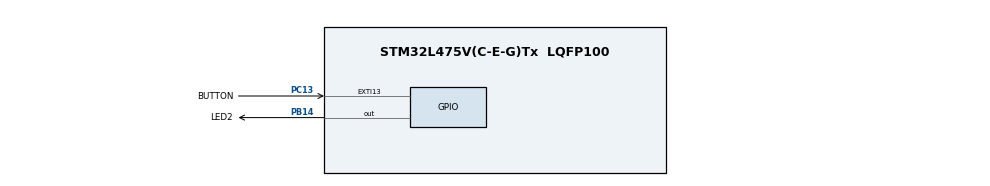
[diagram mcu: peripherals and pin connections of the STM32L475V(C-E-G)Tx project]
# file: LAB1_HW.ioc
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FREERTOS.Tasks01=defaultTask,24,128,StartDefaultTask,Default,NULL,Dynamic,NULL,NULL;myTask02,24,128,StartTask02,Default,NULL,Dynamic,NULL,NULL
Mcu.Family=STM32L4
Mcu.Name=STM32L475V(C-E-G)Tx
Mcu.Package=LQFP100
NVIC.EXTI15_10_IRQn=true\:5\:0\:false\:false\:true\:true\:true\:true\:true
NVIC.PriorityGroup=NVIC_PRIORITYGROUP_4
NVIC.TIM2_IRQn=true\:5\:0\:false\:false\:true\:true\:true\:true\:true
PA13\ (JTMS-SWDIO).Mode=Serial_Wire
PA13\ (JTMS-SWDIO).Signal=SYS_JTMS-SWDIO
PA14\ (JTCK-SWCLK).Mode=Serial_Wire
PA14\ (JTCK-SWCLK).Signal=SYS_JTCK-SWCLK
PB14.GPIO_Label=LED2
PB14.Signal=GPIO_Output
PC13.GPIO_Label=BUTTON
PC13.GPIO_ModeDefaultEXTI=GPIO_MODE_IT_RISING_FALLING
PC13.GPIO_PuPd=GPIO_NOPULL
PC13.Signal=GPXTI13
ProjectManager.HeapSize=0x200
ProjectManager.StackSize=0x400
ProjectManager.TargetToolchain=STM32CubeIDE
RCC.HSE_VALUE=8000000
RCC.HSI_VALUE=16000000
RCC.LSE_VALUE=32768
RCC.MSI_VALUE=4000000
RCC.VCOOutputFreq_Value=32000000
TIM2.AutoReloadPreload=TIM_AUTORELOAD_PRELOAD_ENABLE
TIM2.Period=9999
TIM2.Prescaler=3999
VP_FREERTOS_VS_CMSIS_V2.Mode=CMSIS_V2
VP_TIM2_VS_ClockSourceINT.Mode=Internal
board=custom

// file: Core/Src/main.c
/* USER CODE BEGIN Header */
/**
  ******************************************************************************
  * @file           : main.c
  * @brief          : Main program body
  ******************************************************************************
  * @attention
  *
  * Copyright (c) 2025 STMicroelectronics.
  * All rights reserved.
  *
  * This software is licensed under terms that can be found in the LICENSE file
  * in the root directory of this software component.
  * If no LICENSE file comes with this software, it is provided AS-IS.
  *
  ******************************************************************************
  */
/* USER CODE END Header */
#include "main.h"
#include "cmsis_os.h"

/* USER CODE BEGIN PTD */
#define basic  0
#define QA     1   // option problem_A: long-press detection + queue for Task_1

#define Question QA   // ← 換成 basic / QA 來切題目
// ---- 共用 ----
osSemaphoreId_t semTmr;     // Task_2 (10s) 用
osMutexId_t     mBlink;     // 互斥保護整段閃爍
extern TIM_HandleTypeDef htim2;
static volatile uint32_t g_lastBtnTick = 0; // 50 ms debounce（唯一一個）

// ---- basic 專用 ----
#if (Question == basic)
osSemaphoreId_t semBtn;     // Task_1 的按鍵通知
#endif

// ---- QA 專用（題目 A：長/短按用 queue）----
#if (Question == QA)
typedef enum { BTN_SHORT = 0, BTN_LONG = 1 } btn_evt_t;
osMessageQueueId_t qBtn;
osTimerId_t        tLong;         // 1s one-shot RTOS timer
static volatile uint8_t g_btnPressed = 0;
static volatile uint8_t g_longSent   = 0;
static volatile uint32_t g_pressMs = 0;   // 記錄按下當下的毫秒數
/*  提前宣告 callback 原型（讓編譯器知道它的存在） */
static void LongPressTimerCb(void *argument);
#endif
/* USER CODE END PTD */

TIM_HandleTypeDef htim2;

/* Definitions for defaultTask */
osThreadId_t defaultTaskHandle;
const osThreadAttr_t defaultTask_attributes = {
  .name = "defaultTask",
  .stack_size = 128 * 4,
  .priority = (osPriority_t) osPriorityNormal,
};
/* Definitions for myTask02 */
osThreadId_t myTask02Handle;
const osThreadAttr_t myTask02_attributes = {
  .name = "myTask02",
  .stack_size = 128 * 4,
  .priority = (osPriority_t) osPriorityNormal,
};

void SystemClock_Config(void);
static void MX_GPIO_Init(void);
static void MX_TIM2_Init(void);
void StartDefaultTask(void *argument);
void StartTask02(void *argument);

/* USER CODE BEGIN 0 */
#if (Question == QA)
static void LongPressTimerCb(void *argument)
{
    (void)argument;
    g_longSent = 1;
    uint8_t evt = BTN_LONG;
    /* 在 ISR/Timer context 下用 0 timeout 送訊息即可 */
    osMessageQueuePut(qBtn, &evt, 0, 0);
}
#endif
/* USER CODE END 0 */

int main(void)
{

  /* MCU Configuration--------------------------------------------------------*/

  /* Reset of all peripherals, Initializes the Flash interface and the Systick. */
  HAL_Init();

  /* Configure the system clock */
  SystemClock_Config();

  /* Initialize all configured peripherals */
  MX_GPIO_Init();
  MX_TIM2_Init();

  /* Init scheduler */
  osKernelInitialize();

  /* USER CODE BEGIN RTOS_MUTEX */
  mBlink = osMutexNew(NULL);
  /* add mutexes, ... */
  /* USER CODE END RTOS_MUTEX */

  /* USER CODE BEGIN RTOS_SEMAPHORES */
  semTmr = osSemaphoreNew(1, 0, NULL);
  // basic：用 semaphore 通知 Task_1
  #if (Question == basic)
  semBtn = osSemaphoreNew(1, 0, NULL);
  #endif

  // QA：用 queue + 1s timer 通知 Task_1
  #if (Question == QA)
  qBtn  = osMessageQueueNew(4, sizeof(uint8_t), NULL);
  tLong = osTimerNew(LongPressTimerCb, osTimerOnce, NULL, NULL);
  #endif
  /* add semaphores, ... */
  /* USER CODE END RTOS_SEMAPHORES */

  /* USER CODE BEGIN RTOS_TIMERS */
  HAL_TIM_Base_Start_IT(&htim2);
  /* start timers, add new ones, ... */
  /* USER CODE END RTOS_TIMERS */

  /* Create the thread(s) */
  /* creation of defaultTask */
  defaultTaskHandle = osThreadNew(StartDefaultTask, NULL, &defaultTask_attributes);

  /* creation of myTask02 */
  myTask02Handle = osThreadNew(StartTask02, NULL, &myTask02_attributes);

  /* Start scheduler */
  osKernelStart();

  /* We should never get here as control is now taken by the scheduler */

  /* Infinite loop */
  while (1)
  {

  }
}

void SystemClock_Config(void)
{
  RCC_OscInitTypeDef RCC_OscInitStruct = {0};
  RCC_ClkInitTypeDef RCC_ClkInitStruct = {0};

  /** Configure the main internal regulator output voltage
  */
  if (HAL_PWREx_ControlVoltageScaling(PWR_REGULATOR_VOLTAGE_SCALE1) != HAL_OK)
  {
    Error_Handler();
  }

  /** Initializes the RCC Oscillators according to the specified parameters
  * in the RCC_OscInitTypeDef structure.
  */
  RCC_OscInitStruct.OscillatorType = RCC_OSCILLATORTYPE_MSI;
  RCC_OscInitStruct.MSIState = RCC_MSI_ON;
  RCC_OscInitStruct.MSICalibrationValue = 0;
  RCC_OscInitStruct.MSIClockRange = RCC_MSIRANGE_6;
  RCC_OscInitStruct.PLL.PLLState = RCC_PLL_NONE;
  if (HAL_RCC_OscConfig(&RCC_OscInitStruct) != HAL_OK)
  {
    Error_Handler();
  }

  /** Initializes the CPU, AHB and APB buses clocks
  */
  RCC_ClkInitStruct.ClockType = RCC_CLOCKTYPE_HCLK|RCC_CLOCKTYPE_SYSCLK
                              |RCC_CLOCKTYPE_PCLK1|RCC_CLOCKTYPE_PCLK2;
  RCC_ClkInitStruct.SYSCLKSource = RCC_SYSCLKSOURCE_MSI;
  RCC_ClkInitStruct.AHBCLKDivider = RCC_SYSCLK_DIV1;
  RCC_ClkInitStruct.APB1CLKDivider = RCC_HCLK_DIV1;
  RCC_ClkInitStruct.APB2CLKDivider = RCC_HCLK_DIV1;

  if (HAL_RCC_ClockConfig(&RCC_ClkInitStruct, FLASH_LATENCY_0) != HAL_OK)
  {
    Error_Handler();
  }
}

static void MX_TIM2_Init(void)
{

  TIM_ClockConfigTypeDef sClockSourceConfig = {0};
  TIM_MasterConfigTypeDef sMasterConfig = {0};

  htim2.Instance = TIM2;
  htim2.Init.Prescaler = 3999;
  htim2.Init.CounterMode = TIM_COUNTERMODE_UP;
  htim2.Init.Period = 9999;
  htim2.Init.ClockDivision = TIM_CLOCKDIVISION_DIV1;
  htim2.Init.AutoReloadPreload = TIM_AUTORELOAD_PRELOAD_ENABLE;
  if (HAL_TIM_Base_Init(&htim2) != HAL_OK)
  {
    Error_Handler();
  }
  sClockSourceConfig.ClockSource = TIM_CLOCKSOURCE_INTERNAL;
  if (HAL_TIM_ConfigClockSource(&htim2, &sClockSourceConfig) != HAL_OK)
  {
    Error_Handler();
  }
  sMasterConfig.MasterOutputTrigger = TIM_TRGO_RESET;
  sMasterConfig.MasterSlaveMode = TIM_MASTERSLAVEMODE_DISABLE;
  if (HAL_TIMEx_MasterConfigSynchronization(&htim2, &sMasterConfig) != HAL_OK)
  {
    Error_Handler();
  }

}

static void MX_GPIO_Init(void)
{
  GPIO_InitTypeDef GPIO_InitStruct = {0};

  /* GPIO Ports Clock Enable */
  __HAL_RCC_GPIOC_CLK_ENABLE();
  __HAL_RCC_GPIOB_CLK_ENABLE();
  __HAL_RCC_GPIOA_CLK_ENABLE();

  /*Configure GPIO pin Output Level */
  HAL_GPIO_WritePin(LED2_GPIO_Port, LED2_Pin, GPIO_PIN_RESET);

  /*Configure GPIO pin : BUTTON_Pin */
  GPIO_InitStruct.Pin = BUTTON_Pin;
  GPIO_InitStruct.Mode = GPIO_MODE_IT_RISING_FALLING;
  GPIO_InitStruct.Pull = GPIO_NOPULL;
  HAL_GPIO_Init(BUTTON_GPIO_Port, &GPIO_InitStruct);

  /*Configure GPIO pin : LED2_Pin */
  GPIO_InitStruct.Pin = LED2_Pin;
  GPIO_InitStruct.Mode = GPIO_MODE_OUTPUT_PP;
  GPIO_InitStruct.Pull = GPIO_NOPULL;
  GPIO_InitStruct.Speed = GPIO_SPEED_FREQ_LOW;
  HAL_GPIO_Init(LED2_GPIO_Port, &GPIO_InitStruct);

  /* EXTI interrupt init*/
  HAL_NVIC_SetPriority(EXTI15_10_IRQn, 5, 0);
  HAL_NVIC_EnableIRQ(EXTI15_10_IRQn);

}

/* USER CODE BEGIN 4 */
void HAL_GPIO_EXTI_Callback(uint16_t GPIO_Pin)
{
	if (GPIO_Pin != BUTTON_Pin) return; //先確認就是 USER 按鍵
	// 共用：50 ms 去彈保持
	uint32_t now = HAL_GetTick();
	if (now - g_lastBtnTick < 50) return;
	g_lastBtnTick = now;

	#if (Question == basic)
	// basic：只在「按下」那個邊緣才喚醒
	if (HAL_GPIO_ReadPin(BUTTON_GPIO_Port, BUTTON_Pin) == GPIO_PIN_RESET) {
	    osSemaphoreRelease(semBtn);
	}

#elif (Question == QA)
    GPIO_PinState s = HAL_GPIO_ReadPin(BUTTON_GPIO_Port, BUTTON_Pin);

    if (s == GPIO_PIN_RESET) {                // 按下（B-L475E：按下=低）
        if (!g_btnPressed) {
            g_btnPressed = 1;
            g_pressMs    = HAL_GetTick();     // 開始計時（毫秒）
        }
    } else {                                   // 放開（高）
        if (g_btnPressed) {
            g_btnPressed = 0;
            uint32_t dt = HAL_GetTick() - g_pressMs;
            uint8_t evt = (dt >= 1000) ? BTN_LONG : BTN_SHORT;   // 1秒門檻
            osMessageQueuePut(qBtn, &evt, 0, 0);
        }
    }
#endif
}

void HAL_TIM_PeriodElapsedCallback(TIM_HandleTypeDef *htim)
{
    if (htim == &htim2) {                  // your 10s timer
        (void)osSemaphoreRelease(semTmr);  // wake Task_2
    }
}
/* USER CODE END 4 */

void StartDefaultTask(void *argument)
{
  /* USER CODE BEGIN 5 */
  /* Infinite loop */
  for(;;)
  {
#if (Question == basic)
      osSemaphoreAcquire(semBtn, osWaitForever);   // basic：等按鍵
      osMutexAcquire(mBlink, osWaitForever);
      uint32_t t0 = osKernelGetTickCount();
      while ((osKernelGetTickCount() - t0) < 5000) {   // 5 s @ 1 Hz
          HAL_GPIO_TogglePin(LED2_GPIO_Port, LED2_Pin);
          osDelay(500);
      }
      HAL_GPIO_WritePin(LED2_GPIO_Port, LED2_Pin, GPIO_PIN_RESET);
      osMutexRelease(mBlink);

#elif (Question == QA)
      uint8_t evt;
      osMessageQueueGet(qBtn, &evt, NULL, osWaitForever);  // QA：等短/長按事件
      osMutexAcquire(mBlink, osWaitForever);

      if (evt == BTN_SHORT) {           // 5 s @ 1 Hz
          uint32_t t0 = osKernelGetTickCount();
          while ((osKernelGetTickCount() - t0) < 5000) {
              HAL_GPIO_TogglePin(LED2_GPIO_Port, LED2_Pin);
              osDelay(500);
          }
      } else {                           // BTN_LONG → 5 s @ 10 Hz
          uint32_t t0 = osKernelGetTickCount();
          while ((osKernelGetTickCount() - t0) < 5000) {
              HAL_GPIO_TogglePin(LED2_GPIO_Port, LED2_Pin);
              osDelay(50);
          }
      }
      HAL_GPIO_WritePin(LED2_GPIO_Port, LED2_Pin, GPIO_PIN_RESET);
      osMutexRelease(mBlink);
#endif
  }
  /* USER CODE END 5 */
}

void StartTask02(void *argument)
{
  /* USER CODE BEGIN StartTask02 */
  /* Infinite loop */
  for(;;)
  {
      // sleep until timer ISR signals (every 10 s)
      osSemaphoreAcquire(semTmr, osWaitForever);

      // enter critical blinking section
      osMutexAcquire(mBlink, osWaitForever);

      uint32_t t0 = osKernelGetTickCount();
      while ((osKernelGetTickCount() - t0) < 2000) {   // 2 s burst
          HAL_GPIO_TogglePin(LED2_GPIO_Port, LED2_Pin);
          osDelay(50);                                 // 10 Hz blink: 50 ms per half-cycle
      }
      HAL_GPIO_WritePin(LED2_GPIO_Port, LED2_Pin, GPIO_PIN_RESET);

      osMutexRelease(mBlink);
  }
  /* USER CODE END StartTask02 */
}

void Error_Handler(void)
{
  __disable_irq();
  while (1)
  {
  }
}
